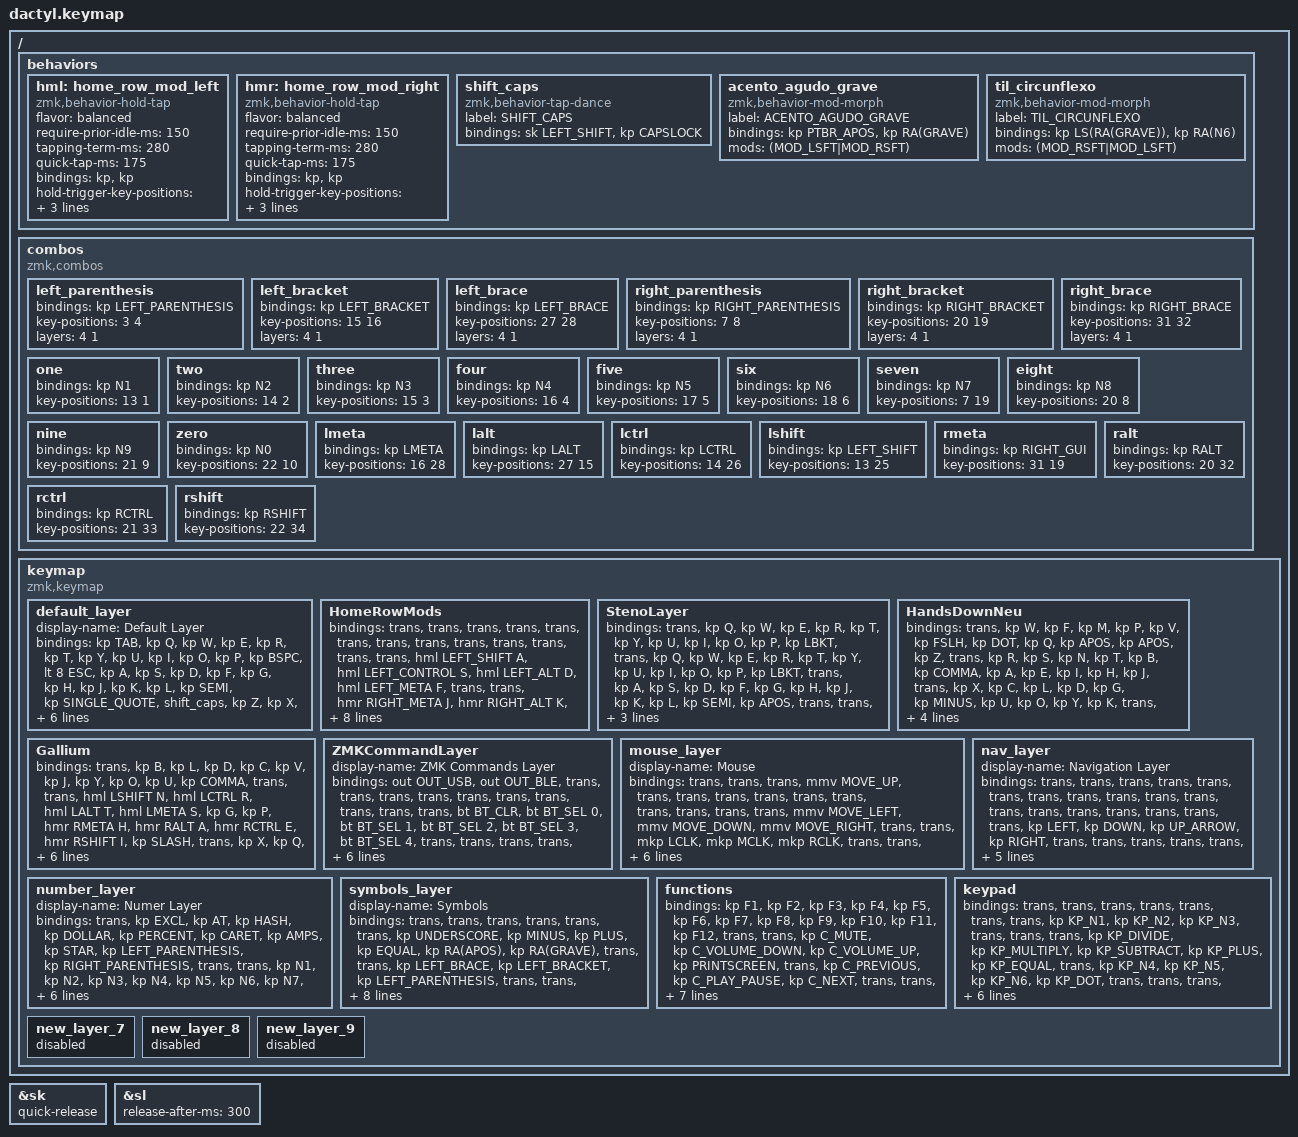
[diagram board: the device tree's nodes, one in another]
#include <behaviors.dtsi>
#include <dt-bindings/zmk/bt.h>
#include <dt-bindings/zmk/keys.h>
#include <dt-bindings/zmk/outputs.h>
#include <dt-bindings/zmk/pointing.h>

#define PTBR_APOS RA(APOS)

&sk { quick-release; };
&sl { release-after-ms = <300>; }; // shorter lingering of modifier

/ {
    behaviors {
        hml: home_row_mod_left {
            compatible = "zmk,behavior-hold-tap";
            #binding-cells = <2>;
            flavor = "balanced";
            require-prior-idle-ms = <150>;
            tapping-term-ms = <280>;
            quick-tap-ms = <175>;
            bindings = <&kp>, <&kp>;

            hold-trigger-key-positions = <6 7 8 9 10 11 18 19 20 21 22 23 30 31 32 33 34 35 40 41 42 43 48 49 50 51 38 39 44 45 46 47>; // List of keys on the right side of the keyboard
            hold-trigger-on-release;
			hold-while-undecided;
        };

        /* shml: shift_home_row_mod_left { */
        /*     compatible = "zmk,behavior-hold-tap"; */
        /*     #binding-cells = <2>; */
        /*     flavor = "hold-preferred"; */
        /*     require-prior-idle-ms = <150>; */
        /*     tapping-term-ms = <280>; */
        /*     quick-tap-ms = <175>; */
        /*     bindings = <&kp>, <&kp>; */
        /*     hold-trigger-key-positions = <6 7 8 9 10 11 18 19 20 21 22 23 30 31 32 33 34 35 40 41 42 43 48 49 50 51 38 39 44 45 46 47>; // List of keys on the right side of the keyboard */
        /* }; */

        hmr: home_row_mod_right {
            compatible = "zmk,behavior-hold-tap";
            #binding-cells = <2>;
            flavor = "balanced";
            require-prior-idle-ms = <150>;
            tapping-term-ms = <280>;
            quick-tap-ms = <175>;
            bindings = <&kp>, <&kp>;

            hold-trigger-key-positions = <0 1 2 3 4 5 12 13 14 15 16 17 24 25 26 27 28 29 36 37 38 39 44 45 46 47 40 41 48 49 50 51>; // List of keys on the left side of the keyboard
            hold-trigger-on-release;
			hold-while-undecided;
        };

        shift_caps: shift_caps {
            compatible = "zmk,behavior-tap-dance";
            label = "SHIFT_CAPS";
            #binding-cells = <0>;
            bindings = <&sk LEFT_SHIFT>, <&kp CAPSLOCK>;
        };

        acento_agudo_grave: acento_agudo_grave {
            compatible = "zmk,behavior-mod-morph";
            label = "ACENTO_AGUDO_GRAVE";
            bindings = <&kp PTBR_APOS>, <&kp RA(GRAVE)>;

            #binding-cells = <0>;
            mods = <(MOD_LSFT|MOD_RSFT)>;
        };

        til_circunflexo: til_circunflexo {
            compatible = "zmk,behavior-mod-morph";
            label = "TIL_CIRCUNFLEXO";
            bindings = <&kp LS(RA(GRAVE))>, <&kp RA(N6)>;

            #binding-cells = <0>;
            mods = <(MOD_RSFT|MOD_LSFT)>;
        };

        /* shmr: shift_home_row_mod_end { */
        /*     compatible = "zmk,behavior-hold-tap"; */
        /*     #binding-cells = <2>; */
        /*     flavor = "hold-preferred"; */
        /*     require-prior-idle-ms = <150>; */
        /*     tapping-term-ms = <280>; */
        /*     quick-tap-ms = <175>; */
        /*     bindings = <&kp>, <&kp>; */
        /*     hold-trigger-key-positions = <0 1 2 3 4 5 12 13 14 15 16 17 24 25 26 27 28 29 36 37 38 39 44 45 46 47 40 41 48 49 50 51>; // List of keys on the left side of the keyboard */
        /* }; */
    };

    combos {
        compatible = "zmk,combos";

        left_parenthesis {
            bindings = <&kp LEFT_PARENTHESIS>;
            key-positions = <3 4>;
            layers = <4 1>;
        };

        left_bracket {
            bindings = <&kp LEFT_BRACKET>;
            key-positions = <15 16>;
            layers = <4 1>;
        };

        left_brace {
            bindings = <&kp LEFT_BRACE>;
            key-positions = <27 28>;
            layers = <4 1>;
        };

        right_parenthesis {
            bindings = <&kp RIGHT_PARENTHESIS>;
            key-positions = <7 8>;
            layers = <4 1>;
        };

        right_bracket {
            bindings = <&kp RIGHT_BRACKET>;
            key-positions = <20 19>;
            layers = <4 1>;
        };

        right_brace {
            bindings = <&kp RIGHT_BRACE>;
            key-positions = <31 32>;
            layers = <4 1>;
        };

        one {
            bindings = <&kp N1>;
            key-positions = <13 1>;

            //timeout-ms = <150>;
        };

        two {
            bindings = <&kp N2>;
            key-positions = <14 2>;

            //timeout-ms = <150>;
        };

        three {
            bindings = <&kp N3>;
            key-positions = <15 3>;

            //timeout-ms = <150>;
        };

        four {
            bindings = <&kp N4>;
            key-positions = <16 4>;

            //timeout-ms = <150>;
        };

        five {
            bindings = <&kp N5>;
            key-positions = <17 5>;

            //timeout-ms = <150>;
        };

        six {
            bindings = <&kp N6>;
            key-positions = <18 6>;

            //timeout-ms = <150>;
        };

        seven {
            bindings = <&kp N7>;
            key-positions = <7 19>;

            //timeout-ms = <150>;
        };

        eight {
            bindings = <&kp N8>;
            key-positions = <20 8>;

            //timeout-ms = <150>;
        };

        nine {
            bindings = <&kp N9>;
            key-positions = <21 9>;

            //timeout-ms = <150>;
        };

        zero {
            bindings = <&kp N0>;
            key-positions = <22 10>;

            //timeout-ms = <150>;
        };

        lmeta {
            bindings = <&kp LMETA>;
            key-positions = <16 28>;
        };

        lalt {
            bindings = <&kp LALT>;
            key-positions = <27 15>;
        };

        lctrl {
            bindings = <&kp LCTRL>;
            key-positions = <14 26>;
        };

        lshift {
            bindings = <&kp LEFT_SHIFT>;
            key-positions = <13 25>;
        };

        rmeta {
            bindings = <&kp RIGHT_GUI>;
            key-positions = <31 19>;
        };

        ralt {
            bindings = <&kp RALT>;
            key-positions = <20 32>;
        };

        rctrl {
            bindings = <&kp RCTRL>;
            key-positions = <21 33>;
        };

        rshift {
            bindings = <&kp RSHIFT>;
            key-positions = <22 34>;
        };

        /* cedilha { */
        /*     bindings = <&kp RA(COMMA)>; */
        /*     key-positions = <26 27>; */
        /* }; */
        /* agudo_grave { */
        /*     bindings = <&acento_agudo_grave>; */
        /*     key-positions = <9 10>; */
        /* }; */
        /* til_circunflexo { */
        /*     bindings = <&til_circunflexo>; */
        /*     key-positions = <21 22>; */
        /* }; */
    };

    keymap {
        compatible = "zmk,keymap";

        default_layer {
            display-name = "Default Layer";
            bindings = <
&kp TAB  &kp Q  &kp W  &kp E  &kp R  &kp T  &kp Y  &kp U  &kp I  &kp O  &kp P  &kp BSPC  &lt 8 ESC  &kp A  &kp S  &kp D  &kp F  &kp G  &kp H  &kp J  &kp K  &kp L  &kp SEMI  &kp SINGLE_QUOTE  &shift_caps  &kp Z  &kp X  &kp C  &kp V  &kp B  &kp N  &kp M  &kp COMMA  &kp DOT  &kp FSLH  &sk RSHIFT  &kp LEFT_CONTROL  &kp LEFT_ALT  &sl 8  &lt 9 SPACE  &lt 7 ENTER  &kp BACKSPACE  &tog 4  &tog 2  &kp LEFT_ALT  &mo 5  &kp LEFT_CONTROL  &mo 11  &mo 6  &kp RIGHT_CONTROL  &mo 5  &tog 1
            >;
        };

        HomeRowMods {
            bindings = <
&trans  &trans  &trans  &trans  &trans  &trans  &trans  &trans  &trans  &trans  &trans  &trans  &trans  &hml LEFT_SHIFT A  &hml LEFT_CONTROL S  &hml LEFT_ALT D  &hml LEFT_META F  &trans  &trans  &hmr RIGHT_META J  &hmr RIGHT_ALT K  &hmr RIGHT_CONTROL L  &hmr RIGHT_SHIFT SEMICOLON  &trans  &trans  &trans  &trans  &trans  &trans  &trans  &trans  &trans  &trans  &trans  &trans  &trans  &trans  &trans  &trans  &trans  &trans  &trans  &trans  &trans  &trans  &trans  &trans  &trans  &trans  &trans  &trans  &trans
            >;

            label = "Home Row Mods";
        };

        StenoLayer {
            bindings = <
&trans  &kp Q  &kp W  &kp E  &kp R  &kp T  &kp Y  &kp U  &kp I  &kp O  &kp P  &kp LBKT  &trans  &kp Q  &kp W  &kp E  &kp R  &kp T  &kp Y  &kp U  &kp I  &kp O  &kp P  &kp LBKT  &trans  &kp A  &kp S  &kp D  &kp F  &kp G  &kp H  &kp J  &kp K  &kp L  &kp SEMI  &kp APOS  &trans  &trans  &kp C  &kp V  &kp N  &kp M  &trans  &trans  &trans  &trans  &trans  &trans  &trans  &trans  &trans  &trans
            >;
        };

        HandsDownNeu {
            bindings = <
&trans  &kp W  &kp F  &kp M  &kp P  &kp V  &kp FSLH  &kp DOT  &kp Q  &kp APOS  &kp APOS  &kp Z  &trans  &kp R  &kp S  &kp N  &kp T  &kp B  &kp COMMA  &kp A  &kp E  &kp I  &kp H  &kp J  &trans  &kp X  &kp C  &kp L  &kp D  &kp G  &kp MINUS  &kp U  &kp O  &kp Y  &kp K  &trans  &trans  &trans  &trans  &trans  &trans  &trans  &trans  &trans  &trans  &trans  &trans  &trans  &trans  &trans  &trans  &trans
            >;

            label = "Hands Down Neu";
        };

        Gallium {
            bindings = <
&trans  &kp B  &kp L  &kp D  &kp C  &kp V  &kp J  &kp Y  &kp O  &kp U  &kp COMMA  &trans  &trans  &hml LSHIFT N  &hml LCTRL R  &hml LALT T  &hml LMETA S  &kp G  &kp P  &hmr RMETA H  &hmr RALT A  &hmr RCTRL E  &hmr RSHIFT I  &kp SLASH  &trans  &kp X  &kp Q  &kp M  &kp W  &kp Z  &kp K  &kp F  &kp APOS  &kp SEMI  &kp DOT  &trans  &trans  &trans  &trans  &trans  &trans  &trans  &trans  &trans  &trans  &trans  &trans  &trans  &trans  &trans  &trans  &trans
            >;

            label = "Gallium";
        };

        ZMKCommandLayer {
            display-name = "ZMK Commands Layer";
            bindings = <
&out OUT_USB  &out OUT_BLE  &trans  &trans  &trans  &trans  &trans  &trans  &trans  &trans  &trans  &trans  &bt BT_CLR  &bt BT_SEL 0  &bt BT_SEL 1  &bt BT_SEL 2  &bt BT_SEL 3  &bt BT_SEL 4  &trans  &trans  &trans  &trans  &trans  &trans  &bt BT_CLR_ALL  &trans  &trans  &trans  &trans  &trans  &trans  &trans  &trans  &trans  &trans  &trans  &studio_unlock  &trans  &trans  &trans  &trans  &trans  &trans  &trans  &trans  &trans  &trans  &trans  &trans  &trans  &trans  &trans
            >;
        };

        mouse_layer {
            display-name = "Mouse";
            bindings = <
&trans  &trans  &trans  &mmv MOVE_UP  &trans  &trans  &trans  &trans  &trans  &trans  &trans  &trans  &trans  &trans  &mmv MOVE_LEFT  &mmv MOVE_DOWN  &mmv MOVE_RIGHT  &trans  &trans  &mkp LCLK  &mkp MCLK  &mkp RCLK  &trans  &trans  &trans  &trans  &trans  &trans  &trans  &trans  &msc SCRL_LEFT  &msc SCRL_DOWN  &msc SCRL_UP  &msc SCRL_RIGHT  &trans  &trans  &trans  &trans  &trans  &trans  &trans  &trans  &trans  &trans  &trans  &trans  &trans  &trans  &trans  &trans  &trans  &trans
            >;
        };

        number_layer {
            display-name = "Numer Layer";
            bindings = <
&trans  &kp EXCL  &kp AT  &kp HASH  &kp DOLLAR  &kp PERCENT  &kp CARET  &kp AMPS  &kp STAR  &kp LEFT_PARENTHESIS  &kp RIGHT_PARENTHESIS  &trans  &trans  &kp N1  &kp N2  &kp N3  &kp N4  &kp N5  &kp N6  &kp N7  &kp N8  &kp N9  &kp N0  &trans  &trans  &trans  &trans  &trans  &trans  &trans  &trans  &trans  &trans  &trans  &trans  &trans  &trans  &trans  &trans  &trans  &trans  &trans  &trans  &trans  &trans  &trans  &trans  &trans  &trans  &trans  &trans  &trans
            >;
        };

        symbols_layer {
            display-name = "Symbols";
            bindings = <
&trans  &trans  &trans  &trans  &trans  &trans  &kp UNDERSCORE  &kp MINUS  &kp PLUS  &kp EQUAL  &kp RA(APOS)  &kp RA(GRAVE)  &trans  &trans  &kp LEFT_BRACE  &kp LEFT_BRACKET  &kp LEFT_PARENTHESIS  &trans  &trans  &kp RIGHT_PARENTHESIS  &kp RIGHT_BRACKET  &kp RA(COMMA)  &kp RA(TILDE)  &kp RA(N6)  &trans  &trans  &trans  &trans  &trans  &trans  &trans  &kp BACKSPACE  &kp DEL  &kp PIPE  &kp BACKSLASH  &trans  &trans  &trans  &trans  &trans  &trans  &trans  &trans  &trans  &trans  &trans  &trans  &trans  &trans  &trans  &trans  &trans
            >;
        };

        nav_layer {
            display-name = "Navigation Layer";
            bindings = <
&trans  &trans  &trans  &trans  &trans  &trans  &trans  &trans  &trans  &trans  &trans  &trans  &trans  &trans  &trans  &trans  &trans  &trans  &kp LEFT  &kp DOWN  &kp UP_ARROW  &kp RIGHT  &trans  &trans  &trans  &trans  &trans  &trans  &trans  &trans  &kp HOME  &kp PAGE_DOWN  &kp PG_UP  &kp END  &trans  &trans  &trans  &trans  &trans  &trans  &trans  &trans  &trans  &trans  &trans  &trans  &trans  &trans  &trans  &trans  &trans  &trans
            >;
        };

        functions {
            bindings = <
&kp F1  &kp F2  &kp F3  &kp F4  &kp F5  &kp F6  &kp F7  &kp F8  &kp F9  &kp F10  &kp F11  &kp F12  &trans  &trans  &kp C_MUTE  &kp C_VOLUME_DOWN  &kp C_VOLUME_UP  &kp PRINTSCREEN  &trans  &kp C_PREVIOUS  &kp C_PLAY_PAUSE  &kp C_NEXT  &trans  &trans  &trans  &trans  &trans  &kp C_BRIGHTNESS_DEC  &kp C_BRIGHTNESS_INC  &trans  &trans  &trans  &trans  &trans  &trans  &trans  &trans  &trans  &trans  &trans  &trans  &trans  &trans  &trans  &trans  &trans  &trans  &trans  &trans  &trans  &trans  &trans
            >;

            label = "functions";
        };

        keypad {
            bindings = <
&trans  &trans  &trans  &trans  &trans  &trans  &trans  &kp KP_N1  &kp KP_N2  &kp KP_N3  &trans  &trans  &trans  &kp KP_DIVIDE  &kp KP_MULTIPLY  &kp KP_SUBTRACT  &kp KP_PLUS  &kp KP_EQUAL  &trans  &kp KP_N4  &kp KP_N5  &kp KP_N6  &kp KP_DOT  &trans  &trans  &trans  &trans  &trans  &trans  &trans  &trans  &kp KP_N7  &kp KP_N8  &kp KP_N9  &kp KP_COMMA  &trans  &trans  &trans  &trans  &trans  &trans  &trans  &kp KP_N0  &trans  &trans  &trans  &trans  &trans  &trans  &trans  &trans  &trans
            >;

            label = "keypad";
        };

        new_layer_7 { status = "reserved"; };

        new_layer_8 { status = "reserved"; };

        new_layer_9 { status = "reserved"; };
    };
};
